AUTOSAR XML (schema 4-2-2)
package /BMW/Platform/Coding/SwcImplementations
  swc implementation IMPL_Coding: behavior=IB_Coding
    code-descriptors:
      code Code: artifact-descriptors=autosar-engineering-object={short-label=Default, category=SWSRC}
package /BMW/Platform/Coding/SwComponentTypes
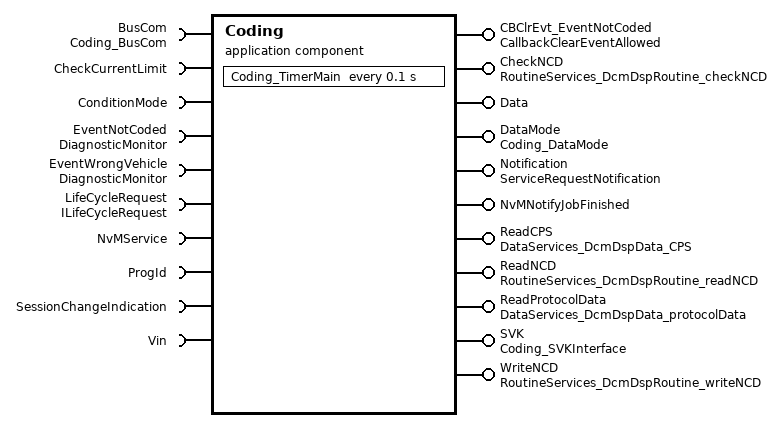
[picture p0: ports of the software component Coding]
  application sw component type Coding
    11 x provide port:
      CBClrEvt_EventNotCoded: server-com-spec{operation=ClearEventAllowed, queue-length=1}, provided-interface=CallbackClearEventAllowed
      CheckNCD: server-com-spec{operation=Start, queue-length=1}, provided-interface=RoutineServices_DcmDspRoutine_checkNCD
      Data: provided-interface=Data
        provided-com-specs:
          operation=GetCurrentLimit, queue-length=1
          operation=GetNAME00_00_CalculationOfLoadMinusstateMinusdependentSteeringAssistance, queue-length=1
          operation=GetNAME00_01_CalculationOfActiveReturn, queue-length=1
          operation=GetNAME00_02_reserved, queue-length=1
          operation=GetNAME00_03_ActiveInfluenceOnTheSteeringHysterisis, queue-length=1
          operation=GetNAME00_{04..07}_reserved, queue-length=1
          operation=GetNAME01_{00..02}_reserved, queue-length=1
          operation=GetNAME01_03_ParkingPowerDamping, queue-length=1
          operation=GetNAME01_{04..07}_reserved, queue-length=1
          operation=GetNAME02_00_CompensationOfFriction, queue-length=1
          operation=GetNAME02_01_CompensationOfConstantSteeringPullAndLateralInclinationPull, queue-length=1
          operation=GetNAME02_02, queue-length=1
          operation=GetNAME02_03, queue-length=1
          operation=GetNAME02_04_CompensationOfInertiaOfTheSteeringGear, queue-length=1
          operation=GetNAME02_05_CompensationOfInertiaOfTheSteeringWheel, queue-length=1
          operation=GetNAME02_06, queue-length=1
          operation=GetNAME02_07, queue-length=1
          operation=GetNAME03_00_reserved, queue-length=1
          operation=GetNAME03_01_VoltageDependantDegredation, queue-length=1
          operation=GetNAME03_02_SpeedDependantDegredation, queue-length=1
          operation=GetNAME03_{03..07}_reserved, queue-length=1
          operation=GetNAME04_00_DrivingDynamicsInterfaceMinusDriversTorque, queue-length=1
          operation=GetNAME04_00_DrivingDynamicsInterfaceMinusMotorTorque, queue-length=1
          operation=GetNAME04_02_DrivingDynamicsInterfaceMinusFactors, queue-length=1
          operation=GetNAME04_03_DrivingDynamicsInterfaceMinusAdditionalDamping, queue-length=1
          operation=GetNAME04_04_EPSVibration, queue-length=1
          operation=GetNAME04_05_DrivingExperienceSwitch, queue-length=1
          operation=GetNAME04_06_reserved, queue-length=1
          operation=GetNAME04_07_automaticEngineStartStopFunction, queue-length=1
          operation=GetNAME05_00_ActiveFanActuation, queue-length=1
          operation=GetNAME05_{01..07}_reserved, queue-length=1
          operation=GetNAME{08..29}_reserved, queue-length=1
          operation=GetSpeedMinuslimitForMaxCurrent, queue-length=1
      DataMode: mode-switch-sender-com-spec{enhanced-mode-api=false, mode-group=currentDataMode, queue-length=2}, provided-interface=Coding_DataMode
      Notification: provided-com-specs=[{operation=Confirmation, queue-length=1}, {operation=Indication, queue-length=1}], provided-interface=ServiceRequestNotification
      NvMNotifyJobFinished: server-com-spec{operation=JobFinished, queue-length=1}, provided-interface=NvMNotifyJobFinished
      ReadCPS: provided-com-specs=[{operation=ConditionCheckRead, queue-length=1}, {operation=ReadData, queue-length=1}], provided-interface=DataServices_DcmDspData_CPS
      ReadNCD: server-com-spec{operation=Start, queue-length=1}, provided-interface=RoutineServices_DcmDspRoutine_readNCD
      ReadProtocolData: provided-com-specs=[{operation=ConditionCheckRead, queue-length=1}, {operation=ReadData, queue-length=1}], provided-interface=DataServices_DcmDspData_protocolData
      SVK: server-com-spec{operation=GetCafIds, queue-length=1}, provided-interface=Coding_SVKInterface
      WriteNCD: server-com-spec{operation=Start, queue-length=1}, provided-interface=RoutineServices_DcmDspRoutine_writeNCD
    provide/require port LifeCycle: mode-switch-sender-com-spec{enhanced-mode-api=true, mode-group=Mode, queue-length=2}, mode-switch-receiver-com-spec{enhanced-mode-api=true, supports-asynchronous-mode-switch=false}, provided-required-interface=ILifeCycle
    10 x require port:
      BusCom: mode-switch-receiver-com-spec{enhanced-mode-api=false, supports-asynchronous-mode-switch=false}, required-interface=Coding_BusCom
      CheckCurrentLimit: client-com-spec=CheckPlausibility, required-interface=CheckCurrentLimit
      ConditionMode: mode-switch-receiver-com-spec{enhanced-mode-api=false, supports-asynchronous-mode-switch=false}, required-interface=ConditionMode
      EventNotCoded: client-com-spec=SetEventStatus, required-interface=DiagnosticMonitor
      EventWrongVehicle: client-com-spec=SetEventStatus, required-interface=DiagnosticMonitor
      LifeCycleRequest: nonqueued-receiver-com-spec{data-element=requestMode, filter=data-filter-type=ALWAYS, init-value=2}, required-interface=ILifeCycleRequest
      NvMService: required-com-specs=[ReadBlock, WriteBlock], required-interface=NvMService
      ProgId: nonqueued-receiver-com-spec{data-element=progId, filter=data-filter-type=ALWAYS, init-value=8 x 0}, required-interface=ProgId
      SessionChangeIndication: mode-switch-receiver-com-spec{enhanced-mode-api=false, supports-asynchronous-mode-switch=false}, required-interface=SessionChangeIndication
      Vin: nonqueued-receiver-com-spec{data-element=Vin, filter=data-filter-type=ALWAYS, init-value={short-label=initVin, fields=[Vin:[Vin1:255, Vin2:255, Vin3:255, Vin4:255, Vin5:255, Vin6:255, Vin7:255], Qualifier:0]}}, required-interface=Vin
    behavior IB_Coding: data-type-mapping=Coding_DataTypeMappingSets
      exclusive area CodingData
      exclusive area CodingState
      operation invoked event E_DemClearEventAllowedNotCoded: start-on-event=Coding_DemClearEventAllowedNotCoded, operation=CBClrEvt_EventNotCoded.ClearEventAllowed
      timing event E_Coding_TimingEvent: disabled-mode=[LifeCycle.Mode.CODING_INITIALIZED, LifeCycle.Mode.CODING_STOPPED], start-on-event=Coding_TimerMain, period=0.1
      operation invoked event E_DCMConfirmation: start-on-event=DCMConfirmation, operation=Notification.Confirmation
      operation invoked event E_DCMIndication: start-on-event=DCMIndication, operation=Notification.Indication
      operation invoked event E_GetCafIds: start-on-event=GetCafIds, operation=SVK.GetCafIds
      data received event LifeCycleRequest: start-on-event=LifeCycleHandler, data=LifeCycleRequest.requestMode
      79 x operation invoked event:
        E_CheckNCD: start-on-event=R_CheckNCD, operation=CheckNCD.Start
        E_ConditionCheckReadCPS: start-on-event=R_ConditionCheckReadCPS, operation=ReadCPS.ConditionCheckRead
        E_ConditionCheckReadProtocolData: start-on-event=R_ConditionCheckReadProtocolData, operation=ReadProtocolData.ConditionCheckRead
        E_GetCurrentLimit: start-on-event=R_GetCurrentLimit, operation=Data.GetCurrentLimit
        E_GetNAME00_00_CalculationOfLoadMinusstateMinusdependentSteeringAssistance: start-on-event=R_GetNAME00_00_CalculationOfLoadMinusstateMinusdependentSteeringAssistance, operation=Data.GetNAME00_00_CalculationOfLoadMinusstateMinusdependentSteeringAssistance
        E_GetNAME00_01_CalculationOfActiveReturn: start-on-event=R_GetNAME00_01_CalculationOfActiveReturn, operation=Data.GetNAME00_01_CalculationOfActiveReturn
        E_GetNAME00_02_reserved: start-on-event=R_GetNAME00_02_reserved, operation=Data.GetNAME00_02_reserved
        E_GetNAME00_03_ActiveInfluenceOnTheSteeringHysterisis: start-on-event=R_GetNAME00_03_ActiveInfluenceOnTheSteeringHysterisis, operation=Data.GetNAME00_03_ActiveInfluenceOnTheSteeringHysterisis
        E_GetNAME00_{04..07}_reserved: start-on-event=R_GetNAME00_{04..07}_reserved, operation=Data.GetNAME00_{04..07}_reserved
        E_GetNAME01_{00..02}_reserved: start-on-event=R_GetNAME01_{00..02}_reserved, operation=Data.GetNAME01_{00..02}_reserved
        E_GetNAME01_03_ParkingPowerDamping: start-on-event=R_GetNAME01_03_ParkingPowerDamping, operation=Data.GetNAME01_03_ParkingPowerDamping
        E_GetNAME01_{04..07}_reserved: start-on-event=R_GetNAME01_{04..07}_reserved, operation=Data.GetNAME01_{04..07}_reserved
        E_GetNAME02_00_CompensationOfFriction: start-on-event=R_GetNAME02_00_CompensationOfFriction, operation=Data.GetNAME02_00_CompensationOfFriction
        E_GetNAME02_01_CompensationOfConstantSteeringPullAndLateralInclinationPull: start-on-event=R_GetNAME02_01_CompensationOfConstantSteeringPullAndLateralInclinationPull, operation=Data.GetNAME02_01_CompensationOfConstantSteeringPullAndLateralInclinationPull
        E_GetNAME02_02: start-on-event=R_GetNAME02_02, operation=Data.GetNAME02_02
        E_GetNAME02_03: start-on-event=R_GetNAME02_03, operation=Data.GetNAME02_03
        E_GetNAME02_04_CompensationOfInertiaOfTheSteeringGear: start-on-event=R_GetNAME02_04_CompensationOfInertiaOfTheSteeringGear, operation=Data.GetNAME02_04_CompensationOfInertiaOfTheSteeringGear
        E_GetNAME02_05_CompensationOfInertiaOfTheSteeringWheel: start-on-event=R_GetNAME02_05_CompensationOfInertiaOfTheSteeringWheel, operation=Data.GetNAME02_05_CompensationOfInertiaOfTheSteeringWheel
        E_GetNAME02_06: start-on-event=R_GetNAME02_06, operation=Data.GetNAME02_06
        E_GetNAME02_07: start-on-event=R_GetNAME02_07, operation=Data.GetNAME02_07
        E_GetNAME03_00_reserved: start-on-event=R_GetNAME03_00_reserved, operation=Data.GetNAME03_00_reserved
        E_GetNAME03_01_VoltageDependantDegredation: start-on-event=R_GetNAME03_01_VoltageDependantDegredation, operation=Data.GetNAME03_01_VoltageDependantDegredation
        E_GetNAME03_02_SpeedDependantDegredation: start-on-event=R_GetNAME03_02_SpeedDependantDegredation, operation=Data.GetNAME03_02_SpeedDependantDegredation
        E_GetNAME03_{03..07}_reserved: start-on-event=R_GetNAME03_{03..07}_reserved, operation=Data.GetNAME03_{03..07}_reserved
        E_GetNAME04_00_DrivingDynamicsInterfaceMinusDriversTorque: start-on-event=R_GetNAME04_00_DrivingDynamicsInterfaceMinusDriversTorque, operation=Data.GetNAME04_00_DrivingDynamicsInterfaceMinusDriversTorque
        E_GetNAME04_00_DrivingDynamicsInterfaceMinusMotorTorque: start-on-event=R_GetNAME04_00_DrivingDynamicsInterfaceMinusMotorTorque, operation=Data.GetNAME04_00_DrivingDynamicsInterfaceMinusMotorTorque
        E_GetNAME04_02_DrivingDynamicsInterfaceMinusFactors: start-on-event=R_GetNAME04_02_DrivingDynamicsInterfaceMinusFactors, operation=Data.GetNAME04_02_DrivingDynamicsInterfaceMinusFactors
        E_GetNAME04_03_DrivingDynamicsInterfaceMinusAdditionalDamping: start-on-event=R_GetNAME04_03_DrivingDynamicsInterfaceMinusAdditionalDamping, operation=Data.GetNAME04_03_DrivingDynamicsInterfaceMinusAdditionalDamping
        E_GetNAME04_04_EPSVibration: start-on-event=R_GetNAME04_04_EPSVibration, operation=Data.GetNAME04_04_EPSVibration
        E_GetNAME04_05_DrivingExperienceSwitch: start-on-event=R_GetNAME04_05_DrivingExperienceSwitch, operation=Data.GetNAME04_05_DrivingExperienceSwitch
        E_GetNAME04_06_reserved: start-on-event=R_GetNAME04_06_reserved, operation=Data.GetNAME04_06_reserved
        E_GetNAME04_07_automaticEngineStartStopFunction: start-on-event=R_GetNAME04_07_automaticEngineStartStopFunction, operation=Data.GetNAME04_07_automaticEngineStartStopFunction
        E_GetNAME05_00_ActiveFanActuation: start-on-event=R_GetNAME05_00_ActiveFanActuation, operation=Data.GetNAME05_00_ActiveFanActuation
        E_GetNAME05_{01..07}_reserved: start-on-event=R_GetNAME05_{01..07}_reserved, operation=Data.GetNAME05_{01..07}_reserved
        E_GetNAME{08..29}_reserved: start-on-event=R_GetNAME{08..29}_reserved, operation=Data.GetNAME{08..29}_reserved
        E_GetSpeedMinuslimitForMaxCurrent: start-on-event=R_GetSpeedMinuslimitForMaxCurrent, operation=Data.GetSpeedMinuslimitForMaxCurrent
        E_ReadCPS: start-on-event=R_ReadCPS, operation=ReadCPS.ReadData
        E_ReadNCD: start-on-event=R_ReadNCD, operation=ReadNCD.Start
        E_ReadProtocolData: start-on-event=R_ReadProtocolData, operation=ReadProtocolData.ReadData
        E_WriteNCD: start-on-event=R_WriteNCD, operation=WriteNCD.Start
      swc mode switch event E_ExitCodingSession: start-on-event=SessionChange, activation=ON-EXIT, mode=SessionChangeIndication.currentSessionMode.CODING_SESSION_ACTIVE
      data received event E_VinReceiveHandler: start-on-event=VinReceiveHandler, data=Vin.Vin
      operation invoked event E_WriteDataBlockNotification: start-on-event=WriteDataBlockNotification, operation=NvMNotifyJobFinished.JobFinished
      port-api-options:
        enable-take-address=false, error-handling=NO-TRANSFORMER-ERROR-HANDLING, indirect-api=false, port=BusCom
        enable-take-address=false, error-handling=NO-TRANSFORMER-ERROR-HANDLING, indirect-api=false, port=CBClrEvt_EventNotCoded
        enable-take-address=false, error-handling=NO-TRANSFORMER-ERROR-HANDLING, indirect-api=false, port=CheckNCD
        enable-take-address=false, error-handling=NO-TRANSFORMER-ERROR-HANDLING, indirect-api=false, port=ConditionMode
        enable-take-address=false, error-handling=NO-TRANSFORMER-ERROR-HANDLING, indirect-api=false, port=Data
        enable-take-address=false, error-handling=NO-TRANSFORMER-ERROR-HANDLING, indirect-api=false, port=EventNotCoded
        enable-take-address=false, error-handling=NO-TRANSFORMER-ERROR-HANDLING, indirect-api=false, port=EventWrongVehicle
        enable-take-address=false, error-handling=NO-TRANSFORMER-ERROR-HANDLING, indirect-api=false, port=LifeCycle
        enable-take-address=false, error-handling=NO-TRANSFORMER-ERROR-HANDLING, indirect-api=false, port=LifeCycleRequest
        enable-take-address=false, error-handling=NO-TRANSFORMER-ERROR-HANDLING, indirect-api=false, port=ReadCPS
        enable-take-address=false, error-handling=NO-TRANSFORMER-ERROR-HANDLING, indirect-api=false, port=SVK
        enable-take-address=false, error-handling=NO-TRANSFORMER-ERROR-HANDLING, indirect-api=false, port=WriteNCD
      88 x runnable:
        Coding_DemClearEventAllowedNotCoded: can-be-invoked-concurrently=true, mode-access-point=DataMode.currentDataMode, symbol=Coding_ClearEventAllowed
        Coding_TimerMain: can-be-invoked-concurrently=true
        DCMConfirmation: symbol=Coding_DCMConfirmation
        DCMIndication: symbol=Coding_DCMIndication
        GetCafIds: can-enter-exclusive-area=CodingData, can-be-invoked-concurrently=true, symbol=Coding_DlogGetCafIds
        LifeCycleHandler: can-enter-exclusive-area=[CodingData, CodingState], mode-access-points=[ConditionMode.currentConditionMode, LifeCycle.Mode, BusCom.Mode], symbol=Coding_LifeCycleHandler
          data-read-access:
            access DRA_requestMode: accessed-variable=LifeCycleRequest.requestMode
          data-receive-point-by-arguments:
            access drparg_progId: accessed-variable=ProgId.progId
          mode switch point MSP_Mode: mode-group=LifeCycle.Mode
          mode switch point currentDataMode: mode-group=DataMode.currentDataMode
          sync call CodingDataWriteBlock: operation=NvMService.WriteBlock, timeout=0
          sync call NotCodedSetEventStatus: operation=EventNotCoded.SetEventStatus, timeout=0
          sync call WrongVehicleSetEventStatus: operation=EventWrongVehicle.SetEventStatus, timeout=0
        R_CheckNCD: can-enter-exclusive-area=CodingData, can-be-invoked-concurrently=true, symbol=Coding_RoutineControlcheckNCD
          sync call CurrentLimit: operation=CheckCurrentLimit.CheckPlausibility, timeout=0
        R_ConditionCheckReadCPS: can-enter-exclusive-area=CodingData, can-be-invoked-concurrently=true, symbol=Coding_ConditionCheckReadCPS
        R_ConditionCheckReadProtocolData: can-be-invoked-concurrently=true, symbol=Coding_ConditionCheckReadProtocolData
        R_GetCurrentLimit: can-be-invoked-concurrently=true, symbol=Coding_Func_GetCurrentLimit
        R_GetNAME00_00_CalculationOfLoadMinusstateMinusdependentSteeringAssistance: can-be-invoked-concurrently=true, symbol=Coding_Func_GetNAME00_00_CalculationOfLoadMinusstateMinusdependentSteeringAssistance
        R_GetNAME00_01_CalculationOfActiveReturn: can-be-invoked-concurrently=true, symbol=Coding_Func_GetNAME00_01_CalculationOfActiveReturn
        R_GetNAME00_02_reserved: can-be-invoked-concurrently=true, symbol=Coding_Func_GetNAME00_02_reserved
        R_GetNAME00_03_ActiveInfluenceOnTheSteeringHysterisis: can-be-invoked-concurrently=true, symbol=Coding_Func_GetNAME00_03_ActiveInfluenceOnTheSteeringHysterisis
        R_GetNAME00_{04..07}_reserved: can-be-invoked-concurrently=true, symbol=Coding_Func_GetNAME00_{04..07}_reserved
        R_GetNAME01_{00..02}_reserved: can-be-invoked-concurrently=true, symbol=Coding_Func_GetNAME01_{00..02}_reserved
        R_GetNAME01_03_ParkingPowerDamping: can-be-invoked-concurrently=true, symbol=Coding_Func_GetNAME01_03_ParkingPowerDamping
        R_GetNAME01_{04..07}_reserved: can-be-invoked-concurrently=true, symbol=Coding_Func_GetNAME01_{04..07}_reserved
        R_GetNAME02_00_CompensationOfFriction: can-be-invoked-concurrently=true, symbol=Coding_Func_GetNAME02_00_CompensationOfFriction
        R_GetNAME02_01_CompensationOfConstantSteeringPullAndLateralInclinationPull: can-be-invoked-concurrently=true, symbol=Coding_Func_GetNAME02_01_CompensationOfConstantSteeringPullAndLateralInclinationPull
        R_GetNAME02_02: can-be-invoked-concurrently=true, symbol=Coding_Func_GetNAME02_02
        R_GetNAME02_03: can-be-invoked-concurrently=true, symbol=Coding_Func_GetNAME02_03
        R_GetNAME02_04_CompensationOfInertiaOfTheSteeringGear: can-be-invoked-concurrently=true, symbol=Coding_Func_GetNAME02_04_CompensationOfInertiaOfTheSteeringGear
        R_GetNAME02_05_CompensationOfInertiaOfTheSteeringWheel: can-be-invoked-concurrently=true, symbol=Coding_Func_GetNAME02_05_CompensationOfInertiaOfTheSteeringWheel
        R_GetNAME02_06: can-be-invoked-concurrently=true, symbol=Coding_Func_GetNAME02_06
        R_GetNAME02_07: can-be-invoked-concurrently=true, symbol=Coding_Func_GetNAME02_07
        R_GetNAME03_00_reserved: can-be-invoked-concurrently=true, symbol=Coding_Func_GetNAME03_00_reserved
        R_GetNAME03_01_VoltageDependantDegredation: can-be-invoked-concurrently=true, symbol=Coding_Func_GetNAME03_01_VoltageDependantDegredation
        R_GetNAME03_02_SpeedDependantDegredation: can-be-invoked-concurrently=true, symbol=Coding_Func_GetNAME03_02_SpeedDependantDegredation
        R_GetNAME03_{03..07}_reserved: can-be-invoked-concurrently=true, symbol=Coding_Func_GetNAME03_{03..07}_reserved
        R_GetNAME04_00_DrivingDynamicsInterfaceMinusDriversTorque: can-be-invoked-concurrently=true, symbol=Coding_Func_GetNAME04_00_DrivingDynamicsInterfaceMinusDriversTorque
        R_GetNAME04_00_DrivingDynamicsInterfaceMinusMotorTorque: can-be-invoked-concurrently=true, symbol=Coding_Func_GetNAME04_00_DrivingDynamicsInterfaceMinusMotorTorque
        R_GetNAME04_02_DrivingDynamicsInterfaceMinusFactors: can-be-invoked-concurrently=true, symbol=Coding_Func_GetNAME04_02_DrivingDynamicsInterfaceMinusFactors
        R_GetNAME04_03_DrivingDynamicsInterfaceMinusAdditionalDamping: can-be-invoked-concurrently=true, symbol=Coding_Func_GetNAME04_03_DrivingDynamicsInterfaceMinusAdditionalDamping
        R_GetNAME04_04_EPSVibration: can-be-invoked-concurrently=true, symbol=Coding_Func_GetNAME04_04_EPSVibration
        R_GetNAME04_05_DrivingExperienceSwitch: can-be-invoked-concurrently=true, symbol=Coding_Func_GetNAME04_05_DrivingExperienceSwitch
        R_GetNAME04_06_reserved: can-be-invoked-concurrently=true, symbol=Coding_Func_GetNAME04_06_reserved
        R_GetNAME04_07_automaticEngineStartStopFunction: can-be-invoked-concurrently=true, symbol=Coding_Func_GetNAME04_07_automaticEngineStartStopFunction
        R_GetNAME05_00_ActiveFanActuation: can-be-invoked-concurrently=true, symbol=Coding_Func_GetNAME05_00_ActiveFanActuation
        R_GetNAME05_{01..07}_reserved: can-be-invoked-concurrently=true, symbol=Coding_Func_GetNAME05_{01..07}_reserved
        R_GetNAME{08..29}_reserved: can-be-invoked-concurrently=true, symbol=Coding_Func_GetNAME{08..29}_reserved
        R_GetSpeedMinuslimitForMaxCurrent: can-be-invoked-concurrently=true, symbol=Coding_Func_GetSpeedMinuslimitForMaxCurrent
        R_ReadCPS: can-enter-exclusive-area=CodingData, can-be-invoked-concurrently=true, symbol=Coding_ReadDataCPS
        R_ReadNCD: can-enter-exclusive-area=CodingData, can-be-invoked-concurrently=true, symbol=Coding_RoutineControlreadNCD
        R_ReadProtocolData: can-be-invoked-concurrently=true, symbol=Coding_ReadDataProtocolData
        R_WriteNCD: can-enter-exclusive-area=CodingData, can-be-invoked-concurrently=true, mode-access-point=DataMode.currentDataMode, symbol=Coding_RoutineControlwriteNCD
          mode switch point currentDataMode: mode-group=DataMode.currentDataMode
        SessionChange: can-enter-exclusive-area=[CodingData, CodingState], can-be-invoked-concurrently=true, mode-access-point=DataMode.currentDataMode, symbol=Coding_SessionChange
          mode switch point currentDataMode: mode-group=DataMode.currentDataMode
          sync call CodingDataReadBlock: operation=NvMService.ReadBlock, timeout=0
          sync call NotCodedSetEventStatus: operation=EventNotCoded.SetEventStatus, timeout=0
        VinReceiveHandler: symbol=Coding_VinReceivedExternalVin
          data-read-access:
            access DRP_Vin: accessed-variable=Vin.Vin
          sync call NotCodedSetEventStatus: operation=EventNotCoded.SetEventStatus, timeout=0
          sync call WrongVehicleSetEventStatus: operation=EventWrongVehicle.SetEventStatus, timeout=0
        WriteDataBlockNotification: can-be-invoked-concurrently=true, mode-access-point=LifeCycle.Mode, symbol=Coding_NvMNotifyJobFinishedCodingData
          data-receive-point-by-arguments:
            access drparg_progId: accessed-variable=ProgId.progId
          sync call CodingDataReadBlock: operation=NvMService.ReadBlock, timeout=0
          sync call NotCodedSetEventStatus: operation=EventNotCoded.SetEventStatus, timeout=0
          sync call WrongVehicleSetEventStatus: operation=EventWrongVehicle.SetEventStatus, timeout=0
      swc service dependency CodingDependencyEvent_NOT_CODED: assigned-ports=role-based-port-assignment={port-prototype=EventNotCoded, role=DiagnosticMonitor}
        service-needs:
          diagnostic event needs CodingDiagnosticEvNeeds: consider-pto-status=false, dtc-kind=NON-EMMISSION-RELATED-DTC
      swc service dependency CodingDependencyEvent_WRONG_VEHICLE: assigned-ports=role-based-port-assignment={port-prototype=EventWrongVehicle, role=DiagnosticMonitor}
        service-needs:
          diagnostic event needs CodingDiagnosticEvNeeds: consider-pto-status=false, dtc-kind=NON-EMMISSION-RELATED-DTC
      swc service dependency CodingDependencyNVM: assigned-ports=role-based-port-assignment={port-prototype=NvMService, role=NvmService}
        service-needs:
          nv block needs CodingNvBlockNeeds: calc-ram-block-crc=false, check-static-block-id=false, n-data-sets=1, n-rom-blocks=0, ram-block-status-control=NV-RAM-MANAGER, readonly=true, reliability=ERROR-DETECTION, resistant-to-changed-sw=false, restore-at-start=true, store-at-shutdown=false, write-only-once=false, write-verification=false, writing-frequency=0, writing-priority=MEDIUM
